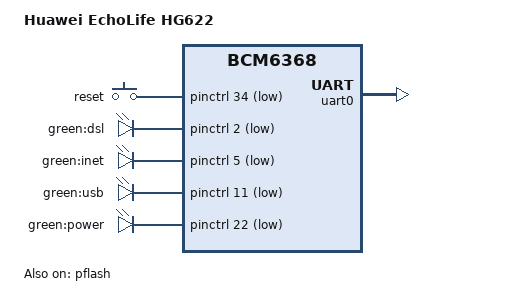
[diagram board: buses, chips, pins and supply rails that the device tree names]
#include "bcm6368.dtsi"

#include <dt-bindings/input/input.h>

/ {
	model = "Huawei EchoLife HG622";
	compatible = "huawei,echolife-hg622", "brcm,bcm6368";

	chosen {
		bootargs = "rootfstype=squashfs,jffs2 noinitrd console=ttyS0,115200";
		stdout-path = "serial0:115200n8";
	};


	keys {
		compatible = "gpio-keys-polled";
		#address-cells = <1>;
		#size-cells = <0>;
		poll-interval = <20>;

		reset {
			label = "reset";
			gpios = <&pinctrl 34 1>;
			linux,code = <KEY_RESTART>;
			debounce-interval = <60>;
		};
	};

	leds {
		compatible = "gpio-leds";

		dsl_green {
			label = "green:dsl";
			gpios = <&pinctrl 2 1>;
		};
		inet_green {
			label = "green:inet";
			gpios = <&pinctrl 5 1>;
		};
		usb_green {
			label = "green:usb";
			gpios = <&pinctrl 11 1>;
		};
		power_green {
			label = "green:power";
			gpios = <&pinctrl 22 1>;
			default-state = "on";
		};
	};
};

&pflash {
	status = "okay";

	partitions {
		compatible = "fixed-partitions";
		#address-cells = <1>;
		#size-cells = <1>;

		cfe@0 {
			label = "CFE";
			reg = <0x000000 0x020000>;
			read-only;
		};

		linux@20000 {
			label = "linux";
			reg = <0x020000 0xf80000>;
			compatible = "brcm,bcm963xx-imagetag";
		};

		cal_data@fa0000 {
			label = "cal_data";
			reg = <0xfa0000 0x020000>;
			read-only;
		};

		nvram@fe0000 {
			label = "nvram";
			reg = <0xfe0000 0x020000>;
		};
	};
};

&pinctrl {
	pinctrl-names = "default";
	pinctrl-0 = <&pinctrl_ephy0_led &pinctrl_ephy1_led
		     &pinctrl_ephy2_led &pinctrl_ephy3_led
		     &pinctrl_pci_gnt0 &pinctrl_pci_req0
		     &pinctrl_pci_intb &pinctrl_pci_gnt1
		     &pinctrl_pci_req1>;
};

&uart0 {
	status = "okay";
};
